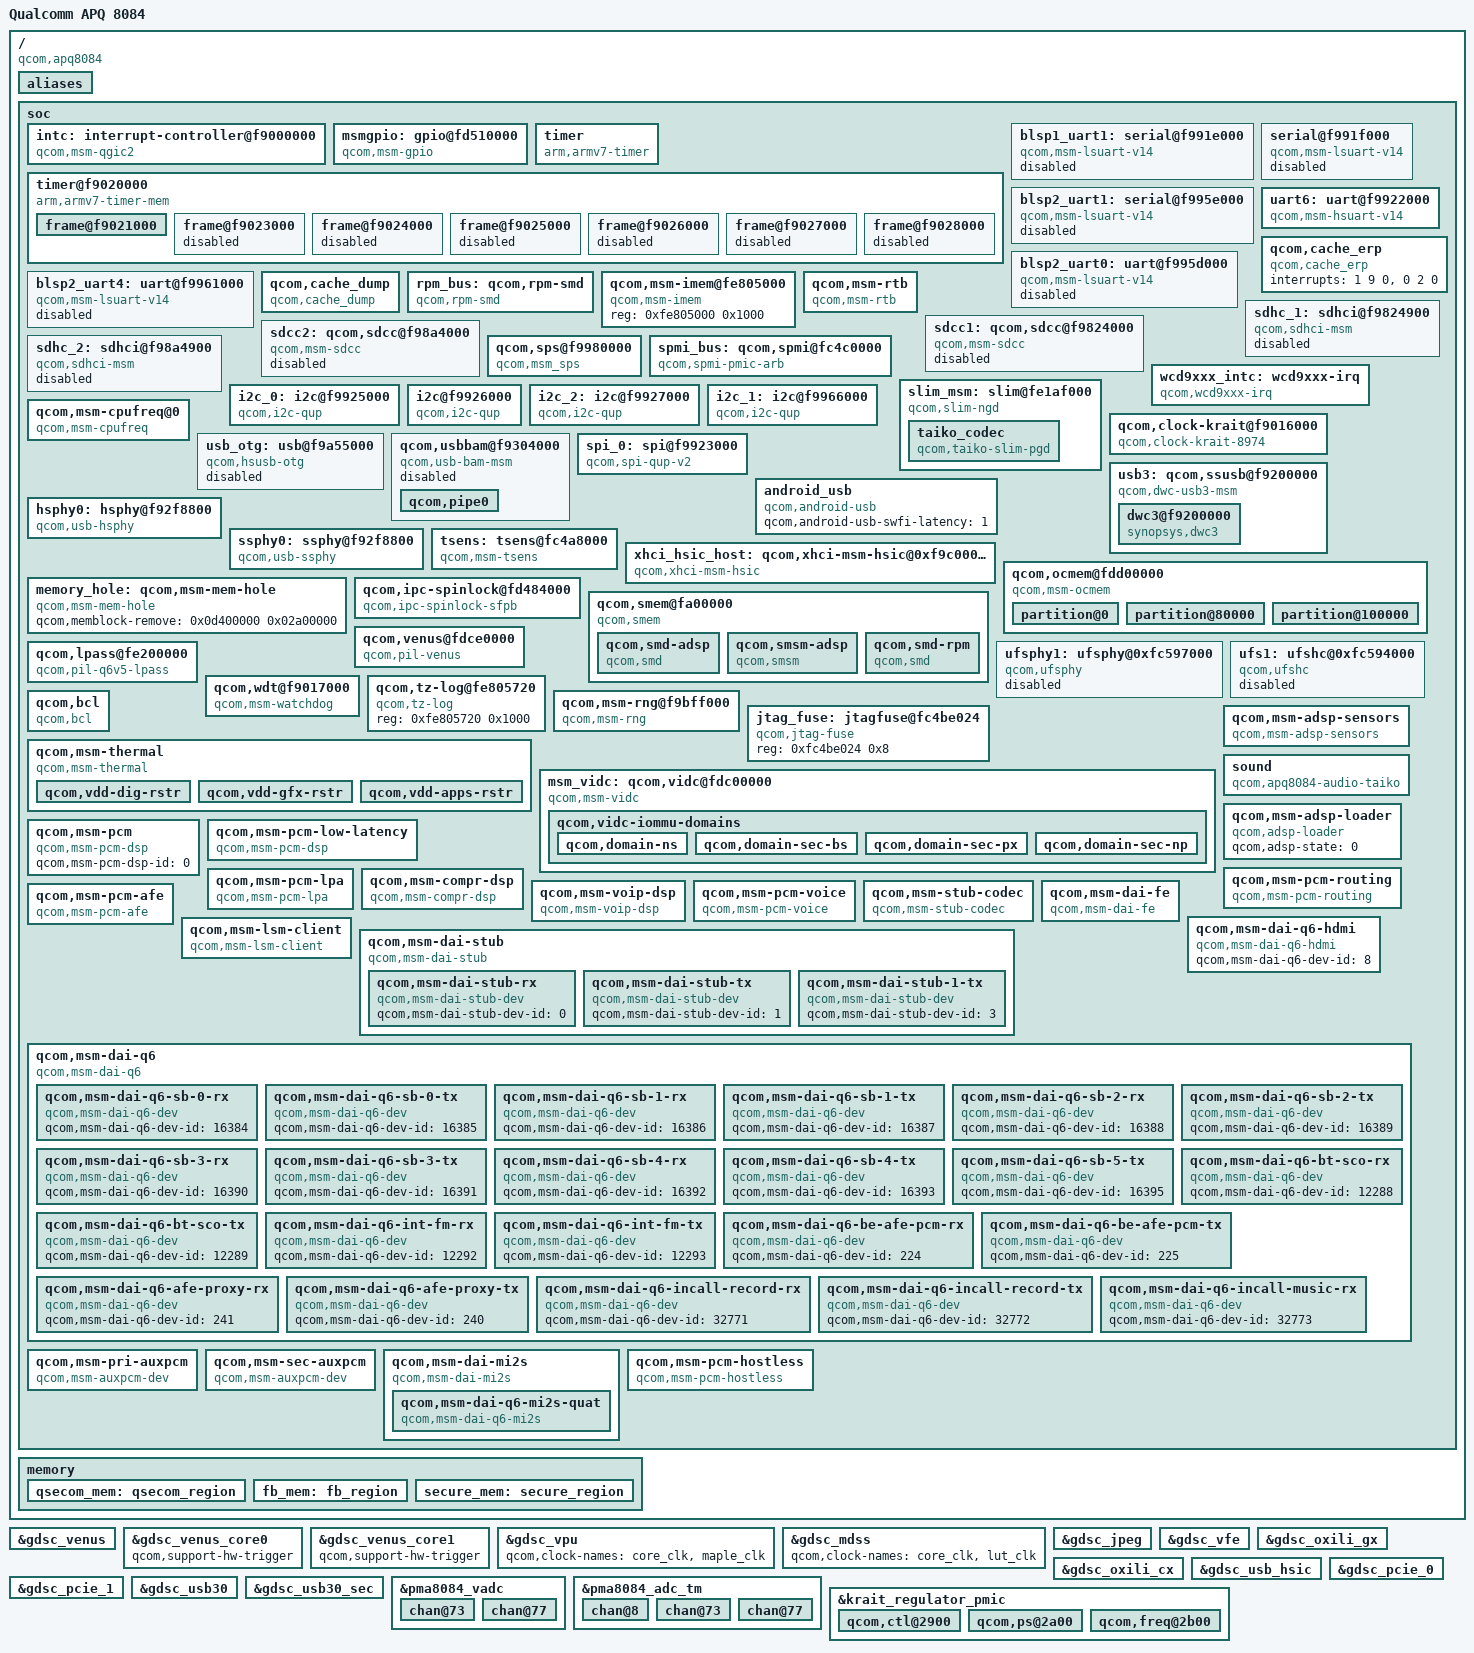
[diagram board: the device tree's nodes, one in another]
/* Copyright (c) 2013, The Linux Foundation. All rights reserved.
 *
 * This program is free software; you can redistribute it and/or modify
 * it under the terms of the GNU General Public License version 2 and
 * only version 2 as published by the Free Software Foundation.
 *
 * This program is distributed in the hope that it will be useful,
 * but WITHOUT ANY WARRANTY; without even the implied warranty of
 * MERCHANTABILITY or FITNESS FOR A PARTICULAR PURPOSE.  See the
 * GNU General Public License for more details.
 */

/include/ "skeleton64.dtsi"

/ {
	model = "Qualcomm APQ 8084";
	compatible = "qcom,apq8084";
	qcom,msm-id = <178 0x10000>;
	interrupt-parent = <&intc>;

	aliases {
		sdhc1 = &sdhc_1; /* SDC1 eMMC slot */
		sdhc2 = &sdhc_2; /* SDC2 SD card slot */
		spi0 = &spi_0;
	};

	soc: soc { };

	memory {
		#address-cells = <2>;
		#size-cells = <2>;

		qsecom_mem: qsecom_region {
			linux,contiguous-region;
			reg = <0 0 0 0x1100000>;
			label = "qseecom_mem";
                };

		fb_mem: fb_region {
			linux,contiguous-region;
			reg = <0 0 0 0x1000000>;
			label = "fb_mem";
			linux,memory-limit = <0xffffffff>;
		};

		secure_mem: secure_region {
			linux,contiguous-region;
			reg = <0 0 0 0xfc00000>;
			label = "secure_mem";
		};
        };
};

/include/ "msm-gdsc.dtsi"
/include/ "apq8084-ion.dtsi"
/include/ "apq8084-iommu.dtsi"
/include/ "apq8084-iommu-domains.dtsi"
/include/ "apq8084-smp2p.dtsi"
/include/ "apq8084-coresight.dtsi"
/include/ "apq8084-mdss.dtsi"
/include/ "apq8084-gpu.dtsi"
/include/ "apq8084-pm.dtsi"
/include/ "apq8084-bus.dtsi"
/include/ "apq8084-iommu-domains.dtsi"

&soc {
	#address-cells = <1>;
	#size-cells = <1>;
	ranges = <0 0 0 0xffffffff>;

	intc: interrupt-controller@f9000000 {
		compatible = "qcom,msm-qgic2";
		interrupt-controller;
		#interrupt-cells = <3>;
		reg = <0xF9000000 0x1000>,
		      <0xF9002000 0x1000>;
	};

	msmgpio: gpio@fd510000 {
		compatible = "qcom,msm-gpio";
		gpio-controller;
		#gpio-cells = <2>;
		interrupt-controller;
		#interrupt-cells = <2>;
		reg = <0xfd510000 0x4000>;
		ngpio = <146>;
		interrupts = <0 208 0>;
		qcom,direct-connect-irqs = <8>;
	};

	timer {
		compatible = "arm,armv7-timer";
		interrupts = <1 2 0xf08>,
			     <1 3 0xf08>,
			     <1 4 0xf08>,
			     <1 1 0xf08>;
		clock-frequency = <19200000>;
	};

	timer@f9020000 {
		#address-cells = <1>;
		#size-cells = <1>;
		ranges;
		compatible = "arm,armv7-timer-mem";
		reg = <0xf9020000 0x1000>;
		clock-frequency = <19200000>;

		frame@f9021000 {
			frame-number = <0>;
			interrupts = <0 8 0x4>,
				     <0 7 0x4>;
			reg = <0xf9021000 0x1000>,
			      <0xf9022000 0x1000>;
		};

		frame@f9023000 {
			frame-number = <1>;
			interrupts = <0 9 0x4>;
			reg = <0xf9023000 0x1000>;
			status = "disabled";
		};

		frame@f9024000 {
			frame-number = <2>;
			interrupts = <0 10 0x4>;
			reg = <0xf9024000 0x1000>;
			status = "disabled";
		};

		frame@f9025000 {
			frame-number = <3>;
			interrupts = <0 11 0x4>;
			reg = <0xf9025000 0x1000>;
			status = "disabled";
		};

		frame@f9026000 {
			frame-number = <4>;
			interrupts = <0 12 0x4>;
			reg = <0xf9026000 0x1000>;
			status = "disabled";
		};

		frame@f9027000 {
			frame-number = <5>;
			interrupts = <0 13 0x4>;
			reg = <0xf9027000 0x1000>;
			status = "disabled";
		};

		frame@f9028000 {
			frame-number = <6>;
			interrupts = <0 14 0x4>;
			reg = <0xf9028000 0x1000>;
			status = "disabled";
		};
	};

        blsp1_uart1: serial@f991e000 {
		compatible = "qcom,msm-lsuart-v14";
		reg = <0xf991e000 0x1000>;
		interrupts = <0 108 0>;
		status = "disabled";
	};

	blsp2_uart1: serial@f995e000 {
		compatible = "qcom,msm-lsuart-v14";
		reg = <0xf995e000 0x1000>;
		interrupts = <0 114 0>;
		status = "disabled";
	};

	blsp2_uart0: uart@f995d000 {
		compatible = "qcom,msm-lsuart-v14";
		reg = <0xf995d000 0x1000>;
		interrupts = <0 113 0>;
		status = "disabled";

		qcom,msm-bus,name = "blsp2_uart0";
		qcom,msm-bus,num-cases = <2>;
		qcom,msm-bus,num-paths = <1>;
		qcom,msm-bus,vectors-KBps =
				<84 512 0 0>,
				<84 512 500 800>;
	};

	serial@f991f000 {
		compatible = "qcom,msm-lsuart-v14";
		reg = <0xf991f000 0x1000>;
		interrupts = <0 109 0>;
		status = "disabled";
	};

	uart6: uart@f9922000 { /* BLSP1 UART6 */
		compatible = "qcom,msm-hsuart-v14";
		reg = <0xf9922000 0x1000>,
			<0xf9904000 0x19000>;
		reg-names = "core_mem", "bam_mem";
		interrupt-names = "core_irq", "bam_irq", "wakeup_irq";
		#address-cells = <0>;
		interrupt-parent = <&uart6>;
		interrupts = <0 1 2>;
		#interrupt-cells = <1>;
		interrupt-map-mask = <0xffffffff>;
		interrupt-map = <0 &intc 0 112 0
						1 &intc 0 238 0
						2 &msmgpio 44 0>;

		qcom,bam-tx-ep-pipe-index = <10>;
		qcom,bam-rx-ep-pipe-index = <11>;
		qcom,msm-bus,name = "uart6";
		qcom,msm-bus,num-cases = <2>;
		qcom,msm-bus,num-paths = <1>;
		qcom,msm-bus,vectors-KBps =
				<86 512 0 0>,
				<86 512 500 800>;
	};

	blsp2_uart4: uart@f9961000 { /* BLSP2 UART4 */
		compatible = "qcom,msm-lsuart-v14";
		reg = <0xf9961000 0x1000>;
		interrupts = <0 117 0>;
		status = "disabled";

		qcom,msm-bus,name = "blsp2_uart4";
		qcom,msm-bus,num-cases = <2>;
		qcom,msm-bus,num-paths = <1>;
		qcom,msm-bus,vectors-KBps =
				<84 512 0 0>,
				<84 512 500 800>;
	};

	qcom,cache_erp {
		compatible = "qcom,cache_erp";
		interrupts = <1 9 0>, <0 2 0>;
		interrupt-names = "l1_irq", "l2_irq";
	};

	qcom,cache_dump {
		compatible = "qcom,cache_dump";
		qcom,l1-dump-size = <0x100000>;
		qcom,l2-dump-size = <0x500000>;
	};

	rpm_bus: qcom,rpm-smd {
		compatible = "qcom,rpm-smd";
		rpm-channel-name = "rpm_requests";
		rpm-channel-type = <15>; /* SMD_APPS_RPM */
	};

        qcom,msm-imem@fe805000 {
                compatible = "qcom,msm-imem";
                reg = <0xfe805000 0x1000>; /* Address and size of IMEM */
	};

	qcom,msm-rtb {
		compatible = "qcom,msm-rtb";
		qcom,memory-reservation-type = "EBI1";
		qcom,memory-reservation-size = <0x100000>; /* 1M EBI1 buffer */
	};

	sdcc1: qcom,sdcc@f9824000 {
		cell-index = <1>; /* SDC1 eMMC slot */
		compatible = "qcom,msm-sdcc";
		reg = <0xf9824000 0x800>;
		reg-names = "core_mem";
		interrupts = <0 123 0>;
		interrupt-names = "core_irq";

		qcom,bus-width = <8>;
		status = "disabled";
	};

	sdhc_1: sdhci@f9824900 {
		compatible = "qcom,sdhci-msm";
		reg = <0xf9824900 0x1a0>, <0xf9824000 0x800>;
		reg-names = "hc_mem", "core_mem";

		interrupts = <0 123 0>, <0 138 0>;
		interrupt-names = "hc_irq", "pwr_irq";

		qcom,bus-width = <8>;
		status = "disabled";
	};

	sdcc2: qcom,sdcc@f98a4000 {
		cell-index = <2>; /* SDC2 SD card slot */
		compatible = "qcom,msm-sdcc";
		reg = <0xf98a4000 0x800>;
		reg-names = "core_mem";
		interrupts = <0 125 0>;
		interrupt-names = "core_irq";

		qcom,bus-width = <4>;
		status = "disabled";
	};

	sdhc_2: sdhci@f98a4900 {
		compatible = "qcom,sdhci-msm";
		reg = <0xf98a4900 0x11c>, <0xf98a4000 0x800>;
		reg-names = "hc_mem", "core_mem";

		interrupts = <0 125 0>, <0 221 0>;
		interrupt-names = "hc_irq", "pwr_irq";

		qcom,bus-width = <4>;
		status = "disabled";
	};

	qcom,sps@f9980000 {
		compatible = "qcom,msm_sps";
		reg = <0xf9984000 0x15000>,
		      <0xf9999000 0xb000>;
		interrupts = <0 94 0>;
		qcom,pipe-attr-ee;
	};

	spmi_bus: qcom,spmi@fc4c0000 {
		cell-index = <0>;
		compatible = "qcom,spmi-pmic-arb";
		reg-names = "core", "intr", "cnfg";
		reg = <0xfc4cf000 0x1000>,
		      <0Xfc4cb000 0x1000>,
		      <0Xfc4ca000 0x1000>;
		/* 190,ee0_krait_hlos_spmi_periph_irq */
		/* 187,channel_0_krait_hlos_trans_done_irq */
		interrupts = <0 190 0>, <0 187 0>;
		qcom,pmic-arb-ee = <0>;
		qcom,pmic-arb-channel = <0>;
		#address-cells = <1>;
		#size-cells = <0>;
		interrupt-controller;
		#interrupt-cells = <3>;
	};

	wcd9xxx_intc: wcd9xxx-irq {
		compatible = "qcom,wcd9xxx-irq";
		interrupt-controller;
		#interrupt-cells = <1>;
		interrupt-parent = <&msmgpio>;
		interrupts = <104 0>;
		interrupt-names = "cdc-int";
	};

	slim_msm: slim@fe1af000 {
		cell-index = <1>;
		compatible = "qcom,slim-ngd";
		reg = <0xfe1af000 0x35000>,
		      <0xfe184000 0x20000>;
		reg-names = "slimbus_physical", "slimbus_bam_physical";
		interrupts = <0 163 0>, <0 164 0>;
		interrupt-names = "slimbus_irq", "slimbus_bam_irq";
		qcom,apps-ch-pipes = <0x60000000>;
		qcom,ea-pc = <0xb0>;

		taiko_codec {
			compatible = "qcom,taiko-slim-pgd";
			elemental-addr = [00 01 A0 00 17 02];

			interrupt-parent = <&wcd9xxx_intc>;
			interrupts = <0 1 2 3 4 5 6 7 8 9 10 11 12 13 14 15 16
				      17 18 19 20 21 22 23 24 25 26 27 28>;

			qcom,cdc-reset-gpio = <&msmgpio 101 0>;

			cdc-vdd-buck-supply = <&pma8084_s5>;
			qcom,cdc-vdd-buck-voltage = <2150000 2150000>;
			qcom,cdc-vdd-buck-current = <650000>;

			cdc-vdd-tx-h-supply = <&pma8084_s4>;
			qcom,cdc-vdd-tx-h-voltage = <1800000 1800000>;
			qcom,cdc-vdd-tx-h-current = <25000>;

			cdc-vdd-rx-h-supply = <&pma8084_s4>;
			qcom,cdc-vdd-rx-h-voltage = <1800000 1800000>;
			qcom,cdc-vdd-rx-h-current = <25000>;

			cdc-vddpx-1-supply = <&pma8084_s4>;
			qcom,cdc-vddpx-1-voltage = <1800000 1800000>;
			qcom,cdc-vddpx-1-current = <10000>;

			cdc-vdd-a-1p2v-supply = <&pma8084_l1>;
			qcom,cdc-vdd-a-1p2v-voltage = <1225000 1225000>;
			qcom,cdc-vdd-a-1p2v-current = <10000>;

			cdc-vddcx-1-supply = <&pma8084_l1>;
			qcom,cdc-vddcx-1-voltage = <1225000 1225000>;
			qcom,cdc-vddcx-1-current = <10000>;

			cdc-vddcx-2-supply = <&pma8084_l1>;
			qcom,cdc-vddcx-2-voltage = <1225000 1225000>;
			qcom,cdc-vddcx-2-current = <10000>;

			qcom,cdc-static-supplies = "cdc-vdd-buck",
						   "cdc-vdd-tx-h",
						   "cdc-vdd-rx-h",
						   "cdc-vddpx-1",
						   "cdc-vdd-a-1p2v",
						   "cdc-vddcx-1",
						   "cdc-vddcx-2";

			qcom,cdc-micbias-ldoh-v = <0x3>;
			qcom,cdc-micbias-cfilt1-mv = <1800>;
			qcom,cdc-micbias-cfilt2-mv = <2700>;
			qcom,cdc-micbias-cfilt3-mv = <1800>;
			qcom,cdc-micbias1-cfilt-sel = <0x0>;
			qcom,cdc-micbias2-cfilt-sel = <0x1>;
			qcom,cdc-micbias3-cfilt-sel = <0x2>;
			qcom,cdc-micbias4-cfilt-sel = <0x2>;
			qcom,cdc-mclk-clk-rate = <9600000>;
			qcom,cdc-slim-ifd = "taiko-slim-ifd";
			qcom,cdc-slim-ifd-elemental-addr = [00 00 A0 00 17 02];
			qcom,cdc-dmic-sample-rate = <4800000>;
		};
	};

	i2c_0: i2c@f9925000 { /* BLSP1 QUP3 */
		cell-index = <0>;
		compatible = "qcom,i2c-qup";
		#address-cells = <1>;
		#size-cells = <0>;
		reg-names = "qup_phys_addr";
		reg = <0xf9925000 0x1000>;
		interrupt-names = "qup_err_intr";
		interrupts = <0 97 0>;
		qcom,i2c-bus-freq = <100000>;
		qcom,i2c-src-freq = <50000000>;
		qcom,sda-gpio = <&msmgpio 10 0>;
		qcom,scl-gpio = <&msmgpio 11 0>;
		qcom,master-id = <86>;
	};

	i2c@f9926000 { /* BLSP-1 QUP-4 */
		cell-index = <3>;
		compatible = "qcom,i2c-qup";
		reg = <0xf9926000 0x1000>;
		#address-cells = <1>;
		#size-cells = <0>;
		reg-names = "qup_phys_addr";
		interrupts = <0 98 0>;
		interrupt-names = "qup_err_intr";
		qcom,i2c-bus-freq = <400000>;
		qcom,i2c-src-freq = <19200000>;
		qcom,sda-gpio = <&msmgpio 29 0>;
		qcom,scl-gpio = <&msmgpio 30 0>;
		qcom,master-id = <86>;
	};

	i2c_2: i2c@f9927000 { /* BLSP1 QUP5 */
		cell-index = <2>;
		compatible = "qcom,i2c-qup";
		#address-cells = <1>;
		#size-cells = <0>;
		reg-names = "qup_phys_addr";
		reg = <0xf9927000 0x1000>;
		interrupt-names = "qup_err_intr";
		interrupts = <0 99 0>;
		qcom,i2c-bus-freq = <100000>;
		qcom,i2c-src-freq = <19200000>;
		qcom,sda-gpio = <&msmgpio 41 0>;
		qcom,scl-gpio = <&msmgpio 42 0>;
		qcom,master-id = <86>;
	};

	i2c_1: i2c@f9966000 { /* BLSP2 QUP4 */
		cell-index = <1>;
		compatible = "qcom,i2c-qup";
		#address-cells = <1>;
		#size-cells = <0>;
		reg-names = "qup_phys_addr";
		reg = <0xf9966000 0x1000>;
		interrupt-names = "qup_err_intr";
		interrupts = <0 104 0>;
		qcom,i2c-bus-freq = <100000>;
		qcom,i2c-src-freq = <50000000>;
		qcom,sda-gpio = <&msmgpio 61 0>;
		qcom,scl-gpio = <&msmgpio 62 0>;
		qcom,master-id = <84>;
	};

	qcom,clock-krait@f9016000 {
		compatible = "qcom,clock-krait-8974";
		reg = <0xf9016000 0x20>,
			<0xf908a000 0x20>,
			<0xf909a000 0x20>,
			<0xf90aa000 0x20>,
			<0xf90ba000 0x20>,
			<0xfc4b80b0 0x08>;
		reg-names = "hfpll_l2_clk", "hfpll0_clk",
				"hfpll1_clk", "hfpll2_clk",
				"hfpll3_clk", "efuse";
		cpu0-supply = <&krait0_vreg>;
		cpu1-supply = <&krait1_vreg>;
		cpu2-supply = <&krait2_vreg>;
		cpu3-supply = <&krait3_vreg>;
		l2-dig-supply = <&pma8084_s2_corner_ao>;
		hfpll-dig-supply = <&pma8084_s2_corner_ao>;
		hfpll-analog-supply = <&pma8084_l12_ao>;
		qcom,hfpll-config-val = <0x04D0405D>;
		qcom,hfpll-user-vco-mask = <0x00100000>;

		qcom,l2-fmax =
			<          0 0			 >,
			<          0 4 /* SVS_SOC */	 >,
			< 1036800000 5 /* NORMAL */	 >,
			< 1728000000 7 /* SUPER_TURBO */ >;

		/*   2.5GHz   */
		qcom,speed1-pvs0-bin-v0 =
			< 0 0 0 >,
			< 300000000 800000 76 >,
			< 345600000 800000 87 >,
			< 422400000 800000 106 >,
			< 499200000 800000 125 >,
			< 576000000 800000 145 >,
			< 652800000 800000 164 >,
			< 729600000 800000 183 >,
			< 806400000 800000 202 >,
			< 883200000 800000 222 >,
			< 960000000 800000 241 >,
			< 1036800000 815000 263 >,
			< 1113600000 830000 286 >,
			< 1190400000 845000 310 >,
			< 1267200000 860000 334 >,
			< 1344000000 875000 359 >,
			< 1420800000 890000 384 >,
			< 1497600000 905000 409 >,
			< 1574400000 920000 436 >,
			< 1651200000 935000 462 >,
			< 1728000000 950000 489 >,
			< 1804800000 965000 517 >;

		qcom,speed1-pvs1-bin-v0 =
			< 0 0 0 >,
			< 300000000 800000 76 >,
			< 345600000 800000 87 >,
			< 422400000 800000 106 >,
			< 499200000 800000 125 >,
			< 576000000 800000 145 >,
			< 652800000 800000 164 >,
			< 729600000 800000 183 >,
			< 806400000 800000 202 >,
			< 883200000 800000 222 >,
			< 960000000 800000 241 >,
			< 1036800000 810000 263 >,
			< 1113600000 825000 286 >,
			< 1190400000 840000 310 >,
			< 1267200000 855000 334 >,
			< 1344000000 870000 359 >,
			< 1420800000 885000 384 >,
			< 1497600000 900000 409 >,
			< 1574400000 910000 436 >,
			< 1651200000 925000 462 >,
			< 1728000000 940000 489 >,
			< 1804800000 955000 517 >;

		qcom,speed1-pvs2-bin-v0 =
			< 0 0 0 >,
			< 300000000 800000 76 >,
			< 345600000 800000 87 >,
			< 422400000 800000 106 >,
			< 499200000 800000 125 >,
			< 576000000 800000 145 >,
			< 652800000 800000 164 >,
			< 729600000 800000 183 >,
			< 806400000 800000 202 >,
			< 883200000 800000 222 >,
			< 960000000 800000 241 >,
			< 1036800000 805000 263 >,
			< 1113600000 820000 286 >,
			< 1190400000 835000 310 >,
			< 1267200000 845000 334 >,
			< 1344000000 860000 359 >,
			< 1420800000 875000 384 >,
			< 1497600000 890000 409 >,
			< 1574400000 905000 436 >,
			< 1651200000 920000 462 >,
			< 1728000000 935000 489 >,
			< 1804800000 950000 517 >;

		qcom,speed1-pvs3-bin-v0 =
			< 0 0 0 >,
			< 300000000 800000 76 >,
			< 345600000 800000 87 >,
			< 422400000 800000 106 >,
			< 499200000 800000 125 >,
			< 576000000 800000 145 >,
			< 652800000 800000 164 >,
			< 729600000 800000 183 >,
			< 806400000 800000 202 >,
			< 883200000 800000 222 >,
			< 960000000 800000 241 >,
			< 1036800000 800000 263 >,
			< 1113600000 815000 286 >,
			< 1190400000 825000 310 >,
			< 1267200000 840000 334 >,
			< 1344000000 855000 359 >,
			< 1420800000 870000 384 >,
			< 1497600000 885000 409 >,
			< 1574400000 895000 436 >,
			< 1651200000 910000 462 >,
			< 1728000000 925000 489 >,
			< 1804800000 940000 517 >;

		qcom,speed1-pvs4-bin-v0 =
			< 0 0 0 >,
			< 300000000 800000 76 >,
			< 345600000 800000 87 >,
			< 422400000 800000 106 >,
			< 499200000 800000 125 >,
			< 576000000 800000 145 >,
			< 652800000 800000 164 >,
			< 729600000 800000 183 >,
			< 806400000 800000 202 >,
			< 883200000 800000 222 >,
			< 960000000 800000 241 >,
			< 1036800000 800000 263 >,
			< 1113600000 805000 286 >,
			< 1190400000 820000 310 >,
			< 1267200000 835000 334 >,
			< 1344000000 850000 359 >,
			< 1420800000 860000 384 >,
			< 1497600000 875000 409 >,
			< 1574400000 890000 436 >,
			< 1651200000 905000 462 >,
			< 1728000000 915000 489 >,
			< 1804800000 930000 517 >;

		qcom,speed1-pvs5-bin-v0 =
			< 0 0 0 >,
			< 300000000 775000 76 >,
			< 345600000 775000 87 >,
			< 422400000 775000 106 >,
			< 499200000 775000 125 >,
			< 576000000 775000 145 >,
			< 652800000 775000 164 >,
			< 729600000 775000 183 >,
			< 806400000 775000 202 >,
			< 883200000 775000 222 >,
			< 960000000 775000 241 >,
			< 1036800000 790000 263 >,
			< 1113600000 800000 286 >,
			< 1190400000 815000 310 >,
			< 1267200000 830000 334 >,
			< 1344000000 840000 359 >,
			< 1420800000 855000 384 >,
			< 1497600000 870000 409 >,
			< 1574400000 880000 436 >,
			< 1651200000 895000 462 >,
			< 1728000000 910000 489 >,
			< 1804800000 920000 517 >;

		qcom,speed1-pvs6-bin-v0 =
			< 0 0 0 >,
			< 300000000 775000 76 >,
			< 345600000 775000 87 >,
			< 422400000 775000 106 >,
			< 499200000 775000 125 >,
			< 576000000 775000 145 >,
			< 652800000 775000 164 >,
			< 729600000 775000 183 >,
			< 806400000 775000 202 >,
			< 883200000 775000 222 >,
			< 960000000 775000 241 >,
			< 1036800000 785000 263 >,
			< 1113600000 795000 286 >,
			< 1190400000 810000 310 >,
			< 1267200000 820000 334 >,
			< 1344000000 835000 359 >,
			< 1420800000 850000 384 >,
			< 1497600000 860000 409 >,
			< 1574400000 875000 436 >,
			< 1651200000 885000 462 >,
			< 1728000000 900000 489 >,
			< 1804800000 915000 517 >;

		qcom,speed1-pvs7-bin-v0 =
			< 0 0 0 >,
			< 300000000 775000 76 >,
			< 345600000 775000 87 >,
			< 422400000 775000 106 >,
			< 499200000 775000 125 >,
			< 576000000 775000 145 >,
			< 652800000 775000 164 >,
			< 729600000 775000 183 >,
			< 806400000 775000 202 >,
			< 883200000 775000 222 >,
			< 960000000 775000 241 >,
			< 1036800000 780000 263 >,
			< 1113600000 790000 286 >,
			< 1190400000 805000 310 >,
			< 1267200000 815000 334 >,
			< 1344000000 830000 359 >,
			< 1420800000 840000 384 >,
			< 1497600000 855000 409 >,
			< 1574400000 865000 436 >,
			< 1651200000 880000 462 >,
			< 1728000000 890000 489 >,
			< 1804800000 905000 517 >;

		qcom,speed1-pvs8-bin-v0 =
			< 0 0 0 >,
			< 300000000 775000 76 >,
			< 345600000 775000 87 >,
			< 422400000 775000 106 >,
			< 499200000 775000 125 >,
			< 576000000 775000 145 >,
			< 652800000 775000 164 >,
			< 729600000 775000 183 >,
			< 806400000 775000 202 >,
			< 883200000 775000 222 >,
			< 960000000 775000 241 >,
			< 1036800000 775000 263 >,
			< 1113600000 785000 286 >,
			< 1190400000 795000 310 >,
			< 1267200000 810000 334 >,
			< 1344000000 820000 359 >,
			< 1420800000 835000 384 >,
			< 1497600000 845000 409 >,
			< 1574400000 860000 436 >,
			< 1651200000 870000 462 >,
			< 1728000000 885000 489 >,
			< 1804800000 895000 517 >;

		qcom,speed1-pvs9-bin-v0 =
			< 0 0 0 >,
			< 300000000 750000 76 >,
			< 345600000 750000 87 >,
			< 422400000 750000 106 >,
			< 499200000 750000 125 >,
			< 576000000 750000 145 >,
			< 652800000 750000 164 >,
			< 729600000 750000 183 >,
			< 806400000 750000 202 >,
			< 883200000 750000 222 >,
			< 960000000 755000 241 >,
			< 1036800000 765000 263 >,
			< 1113600000 780000 286 >,
			< 1190400000 790000 310 >,
			< 1267200000 805000 334 >,
			< 1344000000 815000 359 >,
			< 1420800000 825000 384 >,
			< 1497600000 840000 409 >,
			< 1574400000 850000 436 >,
			< 1651200000 865000 462 >,
			< 1728000000 875000 489 >,
			< 1804800000 885000 517 >;

		qcom,speed1-pvs10-bin-v0 =
			< 0 0 0 >,
			< 300000000 750000 76 >,
			< 345600000 750000 87 >,
			< 422400000 750000 106 >,
			< 499200000 750000 125 >,
			< 576000000 750000 145 >,
			< 652800000 750000 164 >,
			< 729600000 750000 183 >,
			< 806400000 750000 202 >,
			< 883200000 750000 222 >,
			< 960000000 750000 241 >,
			< 1036800000 760000 263 >,
			< 1113600000 775000 286 >,
			< 1190400000 785000 310 >,
			< 1267200000 795000 334 >,
			< 1344000000 810000 359 >,
			< 1420800000 820000 384 >,
			< 1497600000 830000 409 >,
			< 1574400000 845000 436 >,
			< 1651200000 855000 462 >,
			< 1728000000 865000 489 >,
			< 1804800000 880000 517 >;

		qcom,speed1-pvs11-bin-v0 =
			< 0 0 0 >,
			< 300000000 750000 76 >,
			< 345600000 750000 87 >,
			< 422400000 750000 106 >,
			< 499200000 750000 125 >,
			< 576000000 750000 145 >,
			< 652800000 750000 164 >,
			< 729600000 750000 183 >,
			< 806400000 750000 202 >,
			< 883200000 750000 222 >,
			< 960000000 750000 241 >,
			< 1036800000 755000 263 >,
			< 1113600000 770000 286 >,
			< 1190400000 780000 310 >,
			< 1267200000 790000 334 >,
			< 1344000000 800000 359 >,
			< 1420800000 815000 384 >,
			< 1497600000 825000 409 >,
			< 1574400000 835000 436 >,
			< 1651200000 845000 462 >,
			< 1728000000 860000 489 >,
			< 1804800000 870000 517 >;

		qcom,speed1-pvs12-bin-v0 =
			< 0 0 0 >,
			< 300000000 750000 76 >,
			< 345600000 750000 87 >,
			< 422400000 750000 106 >,
			< 499200000 750000 125 >,
			< 576000000 750000 145 >,
			< 652800000 750000 164 >,
			< 729600000 750000 183 >,
			< 806400000 750000 202 >,
			< 883200000 750000 222 >,
			< 960000000 750000 241 >,
			< 1036800000 750000 263 >,
			< 1113600000 760000 286 >,
			< 1190400000 775000 310 >,
			< 1267200000 785000 334 >,
			< 1344000000 795000 359 >,
			< 1420800000 805000 384 >,
			< 1497600000 815000 409 >,
			< 1574400000 830000 436 >,
			< 1651200000 840000 462 >,
			< 1728000000 850000 489 >,
			< 1804800000 860000 517 >;

		qcom,speed1-pvs13-bin-v0 =
			< 0 0 0 >,
			< 300000000 725000 76 >,
			< 345600000 725000 87 >,
			< 422400000 725000 106 >,
			< 499200000 725000 125 >,
			< 576000000 725000 145 >,
			< 652800000 725000 164 >,
			< 729600000 725000 183 >,
			< 806400000 725000 202 >,
			< 883200000 725000 222 >,
			< 960000000 735000 241 >,
			< 1036800000 745000 263 >,
			< 1113600000 755000 286 >,
			< 1190400000 765000 310 >,
			< 1267200000 780000 334 >,
			< 1344000000 790000 359 >,
			< 1420800000 800000 384 >,
			< 1497600000 810000 409 >,
			< 1574400000 820000 436 >,
			< 1651200000 830000 462 >,
			< 1728000000 840000 489 >,
			< 1804800000 850000 517 >;

		qcom,speed1-pvs14-bin-v0 =
			< 0 0 0 >,
			< 300000000 725000 76 >,
			< 345600000 725000 87 >,
			< 422400000 725000 106 >,
			< 499200000 725000 125 >,
			< 576000000 725000 145 >,
			< 652800000 725000 164 >,
			< 729600000 725000 183 >,
			< 806400000 725000 202 >,
			< 883200000 725000 222 >,
			< 960000000 730000 241 >,
			< 1036800000 740000 263 >,
			< 1113600000 750000 286 >,
			< 1190400000 760000 310 >,
			< 1267200000 770000 334 >,
			< 1344000000 780000 359 >,
			< 1420800000 790000 384 >,
			< 1497600000 800000 409 >,
			< 1574400000 815000 436 >,
			< 1651200000 825000 462 >,
			< 1728000000 835000 489 >,
			< 1804800000 845000 517 >;

		qcom,speed1-pvs15-bin-v0 =
			< 0 0 0 >,
			< 300000000 725000 76 >,
			< 345600000 725000 87 >,
			< 422400000 725000 106 >,
			< 499200000 725000 125 >,
			< 576000000 725000 145 >,
			< 652800000 725000 164 >,
			< 729600000 725000 183 >,
			< 806400000 725000 202 >,
			< 883200000 725000 222 >,
			< 960000000 725000 241 >,
			< 1036800000 735000 263 >,
			< 1113600000 745000 286 >,
			< 1190400000 755000 310 >,
			< 1267200000 765000 334 >,
			< 1344000000 775000 359 >,
			< 1420800000 785000 384 >,
			< 1497600000 795000 409 >,
			< 1574400000 805000 436 >,
			< 1651200000 815000 462 >,
			< 1728000000 825000 489 >,
			< 1804800000 835000 517 >;

		/*   2.3GHz   */
		qcom,speed0-pvs0-bin-v0 =
			< 0 0 0 >,
			< 300000000 800000 76 >,
			< 345600000 800000 87 >,
			< 422400000 800000 106 >,
			< 499200000 800000 125 >,
			< 576000000 800000 145 >,
			< 652800000 800000 164 >,
			< 729600000 800000 183 >,
			< 806400000 815000 205 >,
			< 883200000 830000 227 >,
			< 960000000 845000 250 >,
			< 1036800000 860000 273 >,
			< 1113600000 875000 298 >,
			< 1190400000 890000 322 >,
			< 1267200000 905000 346 >,
			< 1344000000 920000 372 >,
			< 1420800000 935000 398 >,
			< 1497600000 950000 424 >,
			< 1574400000 965000 451 >,
			< 1651200000 980000 479 >,
			< 1728000000 995000 506 >,
			< 1804800000 1010000 535 >;

		qcom,speed0-pvs1-bin-v0 =
			< 0 0 0 >,
			< 300000000 800000 76 >,
			< 345600000 800000 87 >,
			< 422400000 800000 106 >,
			< 499200000 800000 125 >,
			< 576000000 800000 145 >,
			< 652800000 800000 164 >,
			< 729600000 800000 183 >,
			< 806400000 810000 205 >,
			< 883200000 825000 227 >,
			< 960000000 840000 250 >,
			< 1036800000 855000 273 >,
			< 1113600000 870000 298 >,
			< 1190400000 885000 322 >,
			< 1267200000 900000 346 >,
			< 1344000000 910000 372 >,
			< 1420800000 925000 398 >,
			< 1497600000 940000 424 >,
			< 1574400000 955000 451 >,
			< 1651200000 970000 479 >,
			< 1728000000 985000 506 >,
			< 1804800000 1000000 535 >;

		qcom,speed0-pvs2-bin-v0 =
			< 0 0 0 >,
			< 300000000 800000 76 >,
			< 345600000 800000 87 >,
			< 422400000 800000 106 >,
			< 499200000 800000 125 >,
			< 576000000 800000 145 >,
			< 652800000 800000 164 >,
			< 729600000 800000 183 >,
			< 806400000 805000 205 >,
			< 883200000 820000 227 >,
			< 960000000 835000 250 >,
			< 1036800000 845000 273 >,
			< 1113600000 860000 298 >,
			< 1190400000 875000 322 >,
			< 1267200000 890000 346 >,
			< 1344000000 905000 372 >,
			< 1420800000 920000 398 >,
			< 1497600000 935000 424 >,
			< 1574400000 950000 451 >,
			< 1651200000 960000 479 >,
			< 1728000000 975000 506 >,
			< 1804800000 990000 535 >;

		qcom,speed0-pvs3-bin-v0 =
			< 0 0 0 >,
			< 300000000 800000 76 >,
			< 345600000 800000 87 >,
			< 422400000 800000 106 >,
			< 499200000 800000 125 >,
			< 576000000 800000 145 >,
			< 652800000 800000 164 >,
			< 729600000 800000 183 >,
			< 806400000 800000 205 >,
			< 883200000 815000 227 >,
			< 960000000 825000 250 >,
			< 1036800000 840000 273 >,
			< 1113600000 855000 298 >,
			< 1190400000 870000 322 >,
			< 1267200000 885000 346 >,
			< 1344000000 895000 372 >,
			< 1420800000 910000 398 >,
			< 1497600000 925000 424 >,
			< 1574400000 940000 451 >,
			< 1651200000 955000 479 >,
			< 1728000000 965000 506 >,
			< 1804800000 980000 535 >;

		qcom,speed0-pvs4-bin-v0 =
			< 0 0 0 >,
			< 300000000 800000 76 >,
			< 345600000 800000 87 >,
			< 422400000 800000 106 >,
			< 499200000 800000 125 >,
			< 576000000 800000 145 >,
			< 652800000 800000 164 >,
			< 729600000 800000 183 >,
			< 806400000 800000 205 >,
			< 883200000 805000 227 >,
			< 960000000 820000 250 >,
			< 1036800000 835000 273 >,
			< 1113600000 850000 298 >,
			< 1190400000 860000 322 >,
			< 1267200000 875000 346 >,
			< 1344000000 890000 372 >,
			< 1420800000 905000 398 >,
			< 1497600000 915000 424 >,
			< 1574400000 930000 451 >,
			< 1651200000 945000 479 >,
			< 1728000000 960000 506 >,
			< 1804800000 970000 535 >;

		qcom,speed0-pvs5-bin-v0 =
			< 0 0 0 >,
			< 300000000 775000 76 >,
			< 345600000 775000 87 >,
			< 422400000 775000 106 >,
			< 499200000 775000 125 >,
			< 576000000 775000 145 >,
			< 652800000 775000 164 >,
			< 729600000 775000 183 >,
			< 806400000 790000 205 >,
			< 883200000 800000 227 >,
			< 960000000 815000 250 >,
			< 1036800000 830000 273 >,
			< 1113600000 840000 298 >,
			< 1190400000 855000 322 >,
			< 1267200000 870000 346 >,
			< 1344000000 880000 372 >,
			< 1420800000 895000 398 >,
			< 1497600000 910000 424 >,
			< 1574400000 920000 451 >,
			< 1651200000 935000 479 >,
			< 1728000000 950000 506 >,
			< 1804800000 960000 535 >;

		qcom,speed0-pvs6-bin-v0 =
			< 0 0 0 >,
			< 300000000 775000 76 >,
			< 345600000 775000 87 >,
			< 422400000 775000 106 >,
			< 499200000 775000 125 >,
			< 576000000 775000 145 >,
			< 652800000 775000 164 >,
			< 729600000 775000 183 >,
			< 806400000 785000 205 >,
			< 883200000 795000 227 >,
			< 960000000 810000 250 >,
			< 1036800000 820000 273 >,
			< 1113600000 835000 298 >,
			< 1190400000 850000 322 >,
			< 1267200000 860000 346 >,
			< 1344000000 875000 372 >,
			< 1420800000 885000 398 >,
			< 1497600000 900000 424 >,
			< 1574400000 915000 451 >,
			< 1651200000 925000 479 >,
			< 1728000000 940000 506 >,
			< 1804800000 950000 535 >;

		qcom,speed0-pvs7-bin-v0 =
			< 0 0 0 >,
			< 300000000 775000 76 >,
			< 345600000 775000 87 >,
			< 422400000 775000 106 >,
			< 499200000 775000 125 >,
			< 576000000 775000 145 >,
			< 652800000 775000 164 >,
			< 729600000 775000 183 >,
			< 806400000 780000 205 >,
			< 883200000 790000 227 >,
			< 960000000 805000 250 >,
			< 1036800000 815000 273 >,
			< 1113600000 830000 298 >,
			< 1190400000 840000 322 >,
			< 1267200000 855000 346 >,
			< 1344000000 865000 372 >,
			< 1420800000 880000 398 >,
			< 1497600000 890000 424 >,
			< 1574400000 905000 451 >,
			< 1651200000 915000 479 >,
			< 1728000000 930000 506 >,
			< 1804800000 940000 535 >;

		qcom,speed0-pvs8-bin-v0 =
			< 0 0 0 >,
			< 300000000 775000 76 >,
			< 345600000 775000 87 >,
			< 422400000 775000 106 >,
			< 499200000 775000 125 >,
			< 576000000 775000 145 >,
			< 652800000 775000 164 >,
			< 729600000 775000 183 >,
			< 806400000 775000 205 >,
			< 883200000 785000 227 >,
			< 960000000 795000 250 >,
			< 1036800000 810000 273 >,
			< 1113600000 820000 298 >,
			< 1190400000 835000 322 >,
			< 1267200000 845000 346 >,
			< 1344000000 860000 372 >,
			< 1420800000 870000 398 >,
			< 1497600000 885000 424 >,
			< 1574400000 895000 451 >,
			< 1651200000 910000 479 >,
			< 1728000000 920000 506 >,
			< 1804800000 935000 535 >;

		qcom,speed0-pvs9-bin-v0 =
			< 0 0 0 >,
			< 300000000 750000 76 >,
			< 345600000 750000 87 >,
			< 422400000 750000 106 >,
			< 499200000 750000 125 >,
			< 576000000 750000 145 >,
			< 652800000 750000 164 >,
			< 729600000 755000 183 >,
			< 806400000 765000 205 >,
			< 883200000 780000 227 >,
			< 960000000 790000 250 >,
			< 1036800000 805000 273 >,
			< 1113600000 815000 298 >,
			< 1190400000 825000 322 >,
			< 1267200000 840000 346 >,
			< 1344000000 850000 372 >,
			< 1420800000 865000 398 >,
			< 1497600000 875000 424 >,
			< 1574400000 885000 451 >,
			< 1651200000 900000 479 >,
			< 1728000000 910000 506 >,
			< 1804800000 925000 535 >;

		qcom,speed0-pvs10-bin-v0 =
			< 0 0 0 >,
			< 300000000 750000 76 >,
			< 345600000 750000 87 >,
			< 422400000 750000 106 >,
			< 499200000 750000 125 >,
			< 576000000 750000 145 >,
			< 652800000 750000 164 >,
			< 729600000 750000 183 >,
			< 806400000 760000 205 >,
			< 883200000 775000 227 >,
			< 960000000 785000 250 >,
			< 1036800000 795000 273 >,
			< 1113600000 810000 298 >,
			< 1190400000 820000 322 >,
			< 1267200000 830000 346 >,
			< 1344000000 845000 372 >,
			< 1420800000 855000 398 >,
			< 1497600000 865000 424 >,
			< 1574400000 880000 451 >,
			< 1651200000 890000 479 >,
			< 1728000000 900000 506 >,
			< 1804800000 915000 535 >;

		qcom,speed0-pvs11-bin-v0 =
			< 0 0 0 >,
			< 300000000 750000 76 >,
			< 345600000 750000 87 >,
			< 422400000 750000 106 >,
			< 499200000 750000 125 >,
			< 576000000 750000 145 >,
			< 652800000 750000 164 >,
			< 729600000 750000 183 >,
			< 806400000 755000 205 >,
			< 883200000 770000 227 >,
			< 960000000 780000 250 >,
			< 1036800000 790000 273 >,
			< 1113600000 800000 298 >,
			< 1190400000 815000 322 >,
			< 1267200000 825000 346 >,
			< 1344000000 835000 372 >,
			< 1420800000 845000 398 >,
			< 1497600000 860000 424 >,
			< 1574400000 870000 451 >,
			< 1651200000 880000 479 >,
			< 1728000000 890000 506 >,
			< 1804800000 905000 535 >;

		qcom,speed0-pvs12-bin-v0 =
			< 0 0 0 >,
			< 300000000 750000 76 >,
			< 345600000 750000 87 >,
			< 422400000 750000 106 >,
			< 499200000 750000 125 >,
			< 576000000 750000 145 >,
			< 652800000 750000 164 >,
			< 729600000 750000 183 >,
			< 806400000 750000 205 >,
			< 883200000 760000 227 >,
			< 960000000 775000 250 >,
			< 1036800000 785000 273 >,
			< 1113600000 795000 298 >,
			< 1190400000 805000 322 >,
			< 1267200000 815000 346 >,
			< 1344000000 830000 372 >,
			< 1420800000 840000 398 >,
			< 1497600000 850000 424 >,
			< 1574400000 860000 451 >,
			< 1651200000 870000 479 >,
			< 1728000000 885000 506 >,
			< 1804800000 895000 535 >;

		qcom,speed0-pvs13-bin-v0 =
			< 0 0 0 >,
			< 300000000 725000 76 >,
			< 345600000 725000 87 >,
			< 422400000 725000 106 >,
			< 499200000 725000 125 >,
			< 576000000 725000 145 >,
			< 652800000 725000 164 >,
			< 729600000 735000 183 >,
			< 806400000 745000 205 >,
			< 883200000 755000 227 >,
			< 960000000 765000 250 >,
			< 1036800000 780000 273 >,
			< 1113600000 790000 298 >,
			< 1190400000 800000 322 >,
			< 1267200000 810000 346 >,
			< 1344000000 820000 372 >,
			< 1420800000 830000 398 >,
			< 1497600000 840000 424 >,
			< 1574400000 850000 451 >,
			< 1651200000 865000 479 >,
			< 1728000000 875000 506 >,
			< 1804800000 885000 535 >;

		qcom,speed0-pvs14-bin-v0 =
			< 0 0 0 >,
			< 300000000 725000 76 >,
			< 345600000 725000 87 >,
			< 422400000 725000 106 >,
			< 499200000 725000 125 >,
			< 576000000 725000 145 >,
			< 652800000 725000 164 >,
			< 729600000 730000 183 >,
			< 806400000 740000 205 >,
			< 883200000 750000 227 >,
			< 960000000 760000 250 >,
			< 1036800000 770000 273 >,
			< 1113600000 780000 298 >,
			< 1190400000 790000 322 >,
			< 1267200000 800000 346 >,
			< 1344000000 815000 372 >,
			< 1420800000 825000 398 >,
			< 1497600000 835000 424 >,
			< 1574400000 845000 451 >,
			< 1651200000 855000 479 >,
			< 1728000000 865000 506 >,
			< 1804800000 875000 535 >;

		qcom,speed0-pvs15-bin-v0 =
			< 0 0 0 >,
			< 300000000 725000 76 >,
			< 345600000 725000 87 >,
			< 422400000 725000 106 >,
			< 499200000 725000 125 >,
			< 576000000 725000 145 >,
			< 652800000 725000 164 >,
			< 729600000 725000 183 >,
			< 806400000 735000 205 >,
			< 883200000 745000 227 >,
			< 960000000 755000 250 >,
			< 1036800000 765000 273 >,
			< 1113600000 775000 298 >,
			< 1190400000 785000 322 >,
			< 1267200000 795000 346 >,
			< 1344000000 805000 372 >,
			< 1420800000 815000 398 >,
			< 1497600000 825000 424 >,
			< 1574400000 835000 451 >,
			< 1651200000 845000 479 >,
			< 1728000000 855000 506 >,
			< 1804800000 865000 535 >;
	};

	qcom,msm-cpufreq@0 {
		reg = <0 4>;
		compatible = "qcom,msm-cpufreq";
		qcom,cpu-mem-ports = <1 512>;
		qcom,cpufreq-table =
			<  300000  300000  600 /*  75 MHz */ >,
			<  422400  422400 1200 /* 150 MHz */ >,
			<  652800  499200 1600 /* 200 MHz */ >,
			<  729600  576000 2456 /* 307 MHz */ >,
			<  883200  576000 2456 /* 307 MHz */ >,
			<  960000  960000 3680 /* 460 MHz */ >,
			< 1036800 1036800 3680 /* 460 MHz */ >,
			< 1190400 1036800 3680 /* 460 MHz */ >,
			< 1267200 1267200 6400 /* 800 MHz */ >,
			< 1497600 1497600 6400 /* 800 MHz */ >,
			< 1574400 1574400 6400 /* 800 MHz */ >,
			< 1728000 1651200 6400 /* 800 MHz */ >,
			< 1958400 1728000 7448 /* 931 MHz */ >,
			< 2265600 1728000 7448 /* 931 MHz */ >;
	};

	usb_otg: usb@f9a55000 {
		status = "disabled";
		compatible = "qcom,hsusb-otg";

		reg = <0xf9a55000 0x400>;
		interrupts = <0 134 0 0 140 0>;
		interrupt-names = "core_irq", "async_irq";
		HSUSB_VDDCX-supply = <&pma8084_s1>;
		HSUSB_1p8-supply = <&pma8084_l6>;
		HSUSB_3p3-supply = <&pma8084_l24>;
		qcom,vdd-voltage-level = <0 900000 1050000>;

		qcom,hsusb-otg-phy-type = <2>;
		qcom,hsusb-otg-mode = <1>;
		qcom,hsusb-otg-otg-control = <3>;
		qcom,hsusb-otg-default-mode = <1>;
		qcom,dp-manual-pullup;

		qcom,msm-bus,name = "usb2";
		qcom,msm-bus,num-cases = <2>;
		qcom,msm-bus,num-paths = <1>;
		qcom,msm-bus,vectors-KBps =
				<87 512 0 0>,
				<87 512 60000 960000>;
	};

	qcom,usbbam@f9304000 {
		status = "disabled";
		compatible = "qcom,usb-bam-msm";
		reg = <0xf9304000 0x5000>,
		      <0xf92f880c 0x4>;
		reg-names = "ssusb", "qscratch_ram1_reg";
		interrupts = <0 132 0>;
		interrupt-names = "ssusb";
		qcom,usb-bam-num-pipes = <16>;
		qcom,usb-bam-fifo-baseaddr = <0x00000000 0xf9200000>;
		qcom,ignore-core-reset-ack;
		qcom,disable-clk-gating;

		qcom,pipe0 {
			label = "ssusb-qdss-in-0";
			qcom,usb-bam-mem-type = <1>;
			qcom,bam-type = <0>;
			qcom,dir = <1>;
			qcom,pipe-num = <0>;
			qcom,peer-bam = <1>;
			qcom,src-bam-physical-address = <0xfc37C000>;
			qcom,src-bam-pipe-index = <0>;
			qcom,dst-bam-physical-address = <0xf9304000>;
			qcom,dst-bam-pipe-index = <2>;
			qcom,data-fifo-offset = <0xf0000>;
			qcom,data-fifo-size = <0x1800>;
			qcom,descriptor-fifo-offset = <0xf4000>;
			qcom,descriptor-fifo-size = <0x1400>;
			qcom,reset-bam-on-connect;
		};
	};

	spi_0: spi@f9923000 { /* BLSP1 QUP1 */
		compatible = "qcom,spi-qup-v2";
		#address-cells = <1>;
		#size-cells = <0>;
		reg-names = "spi_physical", "spi_bam_physical";
		reg = <0xf9923000 0x1000>,
		      <0xf9904000 0xf000>;
		interrupt-names = "spi_irq", "spi_bam_irq";
		interrupts = <0 95 0>, <0 238 0>;
		spi-max-frequency = <19200000>;
		qcom,gpio-mosi = <&msmgpio 0 0>;
		qcom,gpio-miso = <&msmgpio 1 0>;
		qcom,gpio-clk  = <&msmgpio 3 0>;
		qcom,gpio-cs0  = <&msmgpio 0 0>;

		qcom,infinite-mode = <0>;
		qcom,use-bam;
		qcom,ver-reg-exists;
		qcom,bam-consumer-pipe-index = <12>;
		qcom,bam-producer-pipe-index = <13>;
		qcom,master-id = <86>;
	};

	usb3: qcom,ssusb@f9200000 {
		compatible = "qcom,dwc-usb3-msm";
		reg = <0xf9200000 0xfc000>,
			 <0xfd4ab000 0x4>;
		#address-cells = <1>;
		#size-cells = <1>;
		ranges;

		interrupt-parent = <&usb3>;
		interrupts = <0 1>;
		#interrupt-cells = <1>;
		interrupt-map-mask = <0x0 0xffffffff>;
		interrupt-map = <0x0 0 &intc 0 133 0
				 0x0 1 &spmi_bus 0x0 0x0 0x9 0x0>;
		interrupt-names = "hs_phy_irq", "pmic_id_irq";

		USB3_GDSC-supply = <&gdsc_usb30>;
		qcom,dwc-usb3-msm-dbm-eps = <4>;
		qcom,otg-capability;
		qcom,misc-ref = <&pma8084_misc>;
		qcom,restore-sec-cfg-for-scm-dev-id = <9>;

		qcom,msm-bus,name = "usb3";
		qcom,msm-bus,num-cases = <2>;
		qcom,msm-bus,num-paths = <1>;
		qcom,msm-bus,vectors-KBps =
				<61 512 0 0>,
				<61 512 240000 960000>;

		dwc3@f9200000 {
			compatible = "synopsys,dwc3";
			reg = <0xf9200000 0xfc000>;
			interrupt-parent = <&intc>;
			interrupts = <0 131 0>, <0 179 0>;
			interrupt-names = "irq", "otg_irq";
			tx-fifo-resize;
			usb-phy = <&hsphy0>, <&ssphy0>;
		};
	};

	android_usb {
		compatible = "qcom,android-usb";
		qcom,android-usb-swfi-latency = <1>;
	};

	hsphy0: hsphy@f92f8800 {
		compatible = "qcom,usb-hsphy";
		reg = <0xf92f8800 0x3ff>,
			<0xfd4ab204 0x4>;
		qcom,hsphy-init = <0x00D191A4>;
		vdd-supply = <&pma8084_s1>;
		vdda18-supply = <&pma8084_l6>;
		vdda33-supply = <&pma8084_l24>;
		qcom,vdd-voltage-level = <0 900000 1050000>;
		qcom,ext-vbus-id;
		qcom,vbus-valid-override;
	};

	ssphy0: ssphy@f92f8800 {
		compatible = "qcom,usb-ssphy";
		reg = <0xf92f8800 0x3ff>;
		vdd-supply = <&pma8084_s1>;
		vdda18-supply = <&pma8084_l6>;
		qcom,vdd-voltage-level = <0 900000 1050000>;
		qcom,vbus-valid-override;
	};

	tsens: tsens@fc4a8000 {
		compatible = "qcom,msm-tsens";
		reg = <0xfc4a8000 0x2000>,
		      <0xfc4bc000 0x1000>;
		reg-names = "tsens_physical", "tsens_eeprom_physical";
		interrupts = <0 184 0>;
		qcom,sensors = <11>;
		qcom,slope = <3200 3200 3200 3200 3200 3200 3200 3200 3200
				3200 3200>;
		qcom,calib-mode = "fuse_map1";
	};

	xhci_hsic_host: qcom,xhci-msm-hsic@0xf9c00000 {
		compatible = "qcom,xhci-msm-hsic";
		reg = <0xf9c00000 0xfc000>;
		#address-cells = <0>;
		interrupt-parent = <&xhci_hsic_host>;
		interrupts = <0 1 2>;
		#interrupt-cells = <1>;
		interrupt-map-mask = <0xffffffff>;
		interrupt-map = <0 &intc 0 32 0
				1 &intc 0 29 0
				2 &msmgpio 107 0x4>;
		interrupt-names = "core_irq", "pwr_event_irq", "wakeup_irq";
		hsic-vdd-dig-supply = <&pma8084_s2_corner>;
		hsic-gdsc-supply = <&gdsc_usb_hsic>;
		hsic,strobe-gpio = <&msmgpio 134 0x00>;
		hsic,data-gpio = <&msmgpio 135 0x00>;
		qcom,vdd-voltage-level = <1 5 7>;

		qcom,msm-bus,name = "hsic";
		qcom,msm-bus,num-cases = <2>;
		qcom,msm-bus,num-paths = <1>;
		qcom,msm-bus,vectors-KBps =
				<85 512 0 0>,
			<85 512 40000 160000>;
	};

	qcom,ocmem@fdd00000 {
		compatible = "qcom,msm-ocmem";
		reg = <0xfdd00000 0x2000>,
		      <0xfdd02000 0x2000>,
		      <0xfe039000 0x400>,
		      <0xfec00000 0x200000>;
		reg-names = "ocmem_ctrl_physical", "dm_ctrl_physical", "br_ctrl_physical", "ocmem_physical";
		interrupts = <0 76 0 0 77 0>;
		interrupt-names = "ocmem_irq", "dm_irq";
		qcom,ocmem-num-regions = <0x4>;
		qcom,ocmem-num-macros = <0x20>;
		qcom,resource-type = <0x706d636f>;
		#address-cells = <1>;
		#size-cells = <1>;
		ranges = <0x0 0xfec00000 0x200000>;

		partition@0 {
			reg = <0x0 0x180000>;
			qcom,ocmem-part-name = "graphics";
			qcom,ocmem-part-min = <0x80000>;
		};

		partition@80000 {
			reg = <0x180000 0x80000>;
			qcom,ocmem-part-name = "lp_audio";
			qcom,ocmem-part-min = <0x80000>;
		};

		partition@100000 {
			reg = <0x180000 0x80000>;
			qcom,ocmem-part-name = "video";
			qcom,ocmem-part-min = <0x55000>;
		};

	};

	memory_hole: qcom,msm-mem-hole {
		compatible = "qcom,msm-mem-hole";
		qcom,memblock-remove = <0x0d400000 0x02a00000>; /* Address and Size of Hole */
	};

	qcom,ipc-spinlock@fd484000 {
		compatible = "qcom,ipc-spinlock-sfpb";
		reg = <0xfd484000 0x400>;
		qcom,num-locks = <8>;
	};

	qcom,smem@fa00000 {
		compatible = "qcom,smem";
		reg = <0xfa00000 0x200000>,
			<0xf9011000 0x1000>,
			<0xfc428000 0x4000>;
		reg-names = "smem", "irq-reg-base", "aux-mem1";

		qcom,smd-adsp {
			compatible = "qcom,smd";
			qcom,smd-edge = <1>;
			qcom,smd-irq-offset = <0x8>;
			qcom,smd-irq-bitmask = <0x100>;
			qcom,pil-string = "adsp";
			interrupts = <0 156 1>;
		};

		qcom,smsm-adsp {
			compatible = "qcom,smsm";
			qcom,smsm-edge = <1>;
			qcom,smsm-irq-offset = <0x8>;
			qcom,smsm-irq-bitmask = <0x200>;
			interrupts = <0 157 1>;
		};

		qcom,smd-rpm {
			compatible = "qcom,smd";
			qcom,smd-edge = <15>;
			qcom,smd-irq-offset = <0x8>;
			qcom,smd-irq-bitmask = <0x1>;
			interrupts = <0 168 1>;
			qcom,irq-no-suspend;
		};
	};

	qcom,venus@fdce0000 {
		compatible = "qcom,pil-venus";
		reg = <0xfdce0000 0x4000>,
		      <0xfdc80000 0x400>;
		reg-names = "wrapper_base", "vbif_base";
		vdd-supply = <&gdsc_venus>;

		qcom,firmware-name = "venus";
	};

	qcom,lpass@fe200000 {
		compatible = "qcom,pil-q6v5-lpass";
		reg = <0xfe200000 0x00100>,
		      <0xfd485100 0x00010>,
		      <0xfc4016c0 0x00004>;
		reg-names = "qdsp6_base", "halt_base", "restart_reg";
		vdd_cx-supply = <&pma8084_s2_corner>;
		interrupts = <0 162 1>;

		qcom,firmware-name = "adsp";

		/* GPIO inputs from lpass */
		qcom,gpio-err-fatal = <&smp2pgpio_ssr_smp2p_2_in 0 0>;
		qcom,gpio-proxy-unvote = <&smp2pgpio_ssr_smp2p_2_in 2 0>;
		qcom,gpio-err-ready = <&smp2pgpio_ssr_smp2p_2_in 1 0>;

		/* GPIO output to lpass */
		qcom,gpio-force-stop = <&smp2pgpio_ssr_smp2p_2_out 0 0>;
	};

	ufsphy1: ufsphy@0xfc597000 {
		compatible = "qcom,ufsphy";
		reg = <0xfc597000 0x87c>;
		vdda-phy-supply = <&pma8084_l4>;
		vdda-pll-supply = <&pma8084_l12>;
		vdda-phy-max-microamp = <50000>;
		vdda-pll-max-microamp = <1000>;

		status = "disabled";
	};

	ufs1: ufshc@0xfc594000 {
		compatible = "qcom,ufshc";
		reg = <0xfc594000 0x800>;
		interrupts = <0 28 0>;

		ufs-phy = <&ufsphy1>;
		vcc-supply = <&pma8084_l19>;
		vccq-supply = <&pma8084_l3>;
		vccq2-supply = <&pma8084_s4>;
		vcc-max-microamp = <460000>;
		vccq-max-microamp = <200000>;
		vccq2-max-microamp = <145000>;

		clock-names = "core_clk_src", "core_clk", "bus_clk", "iface_clk",
				"ref_clk", "rx_lane0_sync_clk", "tx_lane0_sync_clk",
				"rx_lane1_sync_clk", "tx_lane1_sync_clk";
		max-clock-frequency-hz = <200000000>, <0>, <0>, <0>,
						<0>, <0>, <0>, <0>, <0>;

		status = "disabled";
	};

	qcom,wdt@f9017000 {
		compatible = "qcom,msm-watchdog";
		reg = <0xf9017000 0x1000>;
		interrupts = <0 3 0>, <0 4 0>;
		qcom,bark-time = <11000>;
		qcom,pet-time = <10000>;
		qcom,ipi-ping;
	};

	qcom,tz-log@fe805720 {
		compatible = "qcom,tz-log";
		reg = <0xfe805720 0x1000>;
	};

	qcom,msm-rng@f9bff000{
		compatible = "qcom,msm-rng";
		reg = <0xf9bff000 0x200>;
		qcom,msm-rng-iface-clk;
	};

	jtag_fuse: jtagfuse@fc4be024 {
		compatible = "qcom,jtag-fuse";
		reg = <0xfc4be024 0x8>;
		reg-names = "fuse-base";
	};

	qcom,bcl {
		compatible = "qcom,bcl";
	};

	qcom,msm-thermal {
		compatible = "qcom,msm-thermal";
		qcom,sensor-id = <5>;
		qcom,poll-ms = <250>;
		qcom,limit-temp = <60>;
		qcom,temp-hysteresis = <10>;
		qcom,freq-step = <2>;
		qcom,freq-control-mask = <0xf>;
		qcom,core-limit-temp = <80>;
		qcom,core-temp-hysteresis = <10>;
		qcom,core-control-mask = <0xe>;
		qcom,hotplug-temp = <110>;
		qcom,hotplug-temp-hysteresis = <20>;
		qcom,cpu-sensors = "tsens_tz_sensor5", "tsens_tz_sensor6",
				"tsens_tz_sensor7", "tsens_tz_sensor8";
		qcom,vdd-restriction-temp = <5>;
		qcom,vdd-restriction-temp-hysteresis = <10>;
		qcom,pmic-sw-mode-temp = <85>;
		qcom,pmic-sw-mode-temp-hysteresis = <75>;
		qcom,pmic-sw-mode-regs = "vdd-dig";

		vdd-dig-supply = <&pma8084_s2_floor_corner>;
		vdd-gfx-supply = <&pma8084_s6_floor_corner>;

		qcom,vdd-dig-rstr{
			qcom,vdd-rstr-reg = "vdd-dig";
			qcom,levels = <5 7 7>; /* Nominal, Super Turbo, Super Turbo */
			qcom,min-level = <1>; /* No Request */
		};

		qcom,vdd-gfx-rstr{
			qcom,vdd-rstr-reg = "vdd-gfx";
			qcom,levels = <5 7 7>; /* Nominal, Super Turbo, Super Turbo */
			qcom,min-level = <1>; /* No Request */
		};

		qcom,vdd-apps-rstr{
			qcom,vdd-rstr-reg = "vdd-apps";
			qcom,levels = <1958400 2150400 2150400>;
			qcom,freq-req;
		};
	};

	msm_vidc: qcom,vidc@fdc00000 {
		compatible = "qcom,msm-vidc";
		reg = <0xfdc00000 0xff000>;
		interrupts = <0 44 0>;
		qcom,hfi = "venus";
		qcom,ocmem-size = <524288>; /* 512 * 1024*/
		qcom,max-hw-load = <1281600>; /* Full 4k @ 30 + 1080p @ 30 */
		qcom,vidc-ns-map = <0x40000000 0x40000000>;
		venus-supply = <&gdsc_venus>;
		venus-core0-supply = <&gdsc_venus_core0>;
		venus-core1-supply = <&gdsc_venus_core1>;
		qcom,clock-names= "core_clk", "core0_clk", "core1_clk", "iface_clk", "bus_clk", "mem_clk";
		qcom,clock-configs = <0x3 0x0 0x0 0x0 0x0 0x0>;
		qcom,load-freq-tbl = <979200 465000000>,
			<783360 465000000>,
			<489600 266670000>,
			<244800 133330000>;
		qcom,bus-ports = <1>;
		qcom,reg-presets = <0x800B0 0x00101001>,
			<0x800B0 0x00101001>,
			<0x800B4 0x00101010>,
			<0x800B8 0x10100010>,
			<0x800BC 0x00001010>,
			<0x800C0 0x1000100f>,
			<0x800C4 0x10000000>,
			<0x800C8 0x10001000>,
			<0x800CC 0x00001000>,
			<0x80070 0x00013FFF>,
			<0x80074 0x000000A4>,
			<0x800A8 0x00003FFF>,
			<0xe0020 0x5555556>,
			<0xe0024 0>,
			<0x80124 0x3>;
		qcom,enc-ocmem-ab-ib = <0 0>,
			<138000 1034000>,
			<414000 1034000>,
			<940000 1034000>,
			<1880000 2068000>,
			<3008000 3309000>,
			<3760000 4136000>,
			<4468000 2457000>;
		qcom,dec-ocmem-ab-ib = <0 0>,
			<176000 519000>,
			<456000 519000>,
			<864000 519000>,
			<1728000 1038000>,
			<2766000 1661000>,
			<3456000 2076000>,
			<3662000 2198000>;
		qcom,enc-ddr-ab-ib = <0 0>,
			<120000 302000>,
			<364000 302000>,
			<804000 302000>,
			<1608000 604000>,
			<2576000 967000>,
			<4680000 1404000>,
			<49880000 1496000>;
		qcom,dec-ddr-ab-ib = <0 0>,
			<208000 303000>,
			<536000 303000>,
			<1012000 303000>,
			<2024000 606000>,
			<3240000 970000>,
			<4048000 1212000>,
			<4264000 1279000>;
		qcom,buffer-type-tz-usage-table = <0x91 0x1>,
			<0x42 0x2>,
			<0x120 0x3>;
		qcom,vidc-iommu-domains {
			qcom,domain-ns {
				qcom,vidc-domain-phandle = <&venus_domain_ns>;
				qcom,vidc-partition-buffer-types = <0x1ff>,
					<0x200>;
			};
			qcom,domain-sec-bs {
				qcom,vidc-domain-phandle = <&venus_domain_sec_bitstream>;
				qcom,vidc-partition-buffer-types = <0x91>;
			};
			qcom,domain-sec-px {
				qcom,vidc-domain-phandle = <&venus_domain_sec_pixel>;
				qcom,vidc-partition-buffer-types = <0x42>;
			};
			qcom,domain-sec-np {
				qcom,vidc-domain-phandle = <&venus_domain_sec_non_pixel>;
				qcom,vidc-partition-buffer-types = <0x120>;
			};
		};
	};

	qcom,msm-adsp-sensors {
		compatible = "qcom,msm-adsp-sensors";
		qcom,src-id = <11>;
		qcom,dst-id = <604>;
		qcom,ab = <32505856>;
		qcom,ib = <32505856>;
	};

	sound {
		compatible = "qcom,apq8084-audio-taiko";
		qcom,model = "apq8084-taiko-snd-card";

		qcom,audio-routing =
			"RX_BIAS", "MCLK",
			"LDO_H", "MCLK",
			"AIF4 MAD", "MCLK",
			"AMIC1", "MIC BIAS1 Internal1",
			"MIC BIAS1 Internal1", "Handset Mic",
			"AMIC2", "MIC BIAS2 External",
			"MIC BIAS2 External", "Headset Mic",
			"AMIC3", "MIC BIAS2 External",
			"MIC BIAS2 External", "ANCRight Headset Mic",
			"AMIC4", "MIC BIAS2 External",
			"MIC BIAS2 External", "ANCLeft Headset Mic",
			"DMIC1", "MIC BIAS3 External",
			"MIC BIAS3 External", "Digital Mic1",
			"DMIC2", "MIC BIAS4 External",
			"MIC BIAS4 External", "Digital Mic2",
			"DMIC3", "MIC BIAS1 External",
			"MIC BIAS1 External", "Digital Mic3",
			"DMIC4", "MIC BIAS1 External",
			"MIC BIAS1 External", "Digital Mic4",
			"DMIC5", "MIC BIAS3 External",
			"MIC BIAS3 External", "Digital Mic5",
			"DMIC6", "MIC BIAS3 External",
			"MIC BIAS3 External", "Digital Mic6";

		qcom,taiko-mclk-clk-freq = <9600000>;
		qcom,prim-auxpcm-gpio-clk  = <&msmgpio 87 0>;
		qcom,prim-auxpcm-gpio-sync = <&msmgpio 88 0>;
		qcom,prim-auxpcm-gpio-din  = <&msmgpio 89 0>;
		qcom,prim-auxpcm-gpio-dout = <&msmgpio 90 0>;
		qcom,prim-auxpcm-gpio-set = "prim-gpio-tert";
		qcom,sec-auxpcm-gpio-clk  = <&msmgpio 82 0>;
		qcom,sec-auxpcm-gpio-sync = <&msmgpio 83 0>;
		qcom,sec-auxpcm-gpio-din  = <&msmgpio 84 0>;
		qcom,sec-auxpcm-gpio-dout = <&msmgpio 85 0>;
	};

	qcom,msm-adsp-loader {
		compatible = "qcom,adsp-loader";
		qcom,adsp-state = <0>;
	};

	qcom,msm-pcm {
		compatible = "qcom,msm-pcm-dsp";
		qcom,msm-pcm-dsp-id = <0>;
	};

	qcom,msm-pcm-low-latency {
		compatible = "qcom,msm-pcm-dsp";
		qcom,msm-pcm-dsp-id = <1>;
		qcom,msm-pcm-low-latency;
	};

	qcom,msm-pcm-routing {
		compatible = "qcom,msm-pcm-routing";
	};

	qcom,msm-pcm-lpa {
		compatible = "qcom,msm-pcm-lpa";
	};

	qcom,msm-compr-dsp {
		compatible = "qcom,msm-compr-dsp";
	};

	qcom,msm-voip-dsp {
		compatible = "qcom,msm-voip-dsp";
	};

	qcom,msm-pcm-voice {
		compatible = "qcom,msm-pcm-voice";
	};

	qcom,msm-stub-codec {
		compatible = "qcom,msm-stub-codec";
	};

	qcom,msm-dai-fe {
		compatible = "qcom,msm-dai-fe";
	};

	qcom,msm-pcm-afe {
		compatible = "qcom,msm-pcm-afe";
	};

	qcom,msm-dai-q6-hdmi {
		compatible = "qcom,msm-dai-q6-hdmi";
		qcom,msm-dai-q6-dev-id = <8>;
	};

	qcom,msm-lsm-client {
		compatible = "qcom,msm-lsm-client";
	};

	qcom,msm-dai-stub {
		compatible = "qcom,msm-dai-stub";
		qcom,msm-dai-stub-rx {
			compatible = "qcom,msm-dai-stub-dev";
			qcom,msm-dai-stub-dev-id = <0>;
		};

		qcom,msm-dai-stub-tx {
			compatible = "qcom,msm-dai-stub-dev";
			qcom,msm-dai-stub-dev-id = <1>;
		};

		qcom,msm-dai-stub-1-tx {
			compatible = "qcom,msm-dai-stub-dev";
			qcom,msm-dai-stub-dev-id = <3>;
		};
	};

	qcom,msm-dai-q6 {
		compatible = "qcom,msm-dai-q6";
		qcom,msm-dai-q6-sb-0-rx {
			compatible = "qcom,msm-dai-q6-dev";
			qcom,msm-dai-q6-dev-id = <16384>;
		};

		qcom,msm-dai-q6-sb-0-tx {
			compatible = "qcom,msm-dai-q6-dev";
			qcom,msm-dai-q6-dev-id = <16385>;
		};

		qcom,msm-dai-q6-sb-1-rx {
			compatible = "qcom,msm-dai-q6-dev";
			qcom,msm-dai-q6-dev-id = <16386>;
		};

		qcom,msm-dai-q6-sb-1-tx {
			compatible = "qcom,msm-dai-q6-dev";
			qcom,msm-dai-q6-dev-id = <16387>;
		};

		qcom,msm-dai-q6-sb-2-rx {
			compatible = "qcom,msm-dai-q6-dev";
			qcom,msm-dai-q6-dev-id = <16388>;
		};

		qcom,msm-dai-q6-sb-2-tx {
			compatible = "qcom,msm-dai-q6-dev";
			qcom,msm-dai-q6-dev-id = <16389>;
		};

		qcom,msm-dai-q6-sb-3-rx {
			compatible = "qcom,msm-dai-q6-dev";
			qcom,msm-dai-q6-dev-id = <16390>;
		};

		qcom,msm-dai-q6-sb-3-tx {
			compatible = "qcom,msm-dai-q6-dev";
			qcom,msm-dai-q6-dev-id = <16391>;
		};

		qcom,msm-dai-q6-sb-4-rx {
			compatible = "qcom,msm-dai-q6-dev";
			qcom,msm-dai-q6-dev-id = <16392>;
		};

		qcom,msm-dai-q6-sb-4-tx {
			compatible = "qcom,msm-dai-q6-dev";
			qcom,msm-dai-q6-dev-id = <16393>;
		};

		qcom,msm-dai-q6-sb-5-tx {
			compatible = "qcom,msm-dai-q6-dev";
			qcom,msm-dai-q6-dev-id = <16395>;
		};

		qcom,msm-dai-q6-bt-sco-rx {
			compatible = "qcom,msm-dai-q6-dev";
			qcom,msm-dai-q6-dev-id = <12288>;
		};

		qcom,msm-dai-q6-bt-sco-tx {
			compatible = "qcom,msm-dai-q6-dev";
			qcom,msm-dai-q6-dev-id = <12289>;
		};

		qcom,msm-dai-q6-int-fm-rx {
			compatible = "qcom,msm-dai-q6-dev";
			qcom,msm-dai-q6-dev-id = <12292>;
		};

		qcom,msm-dai-q6-int-fm-tx {
			compatible = "qcom,msm-dai-q6-dev";
			qcom,msm-dai-q6-dev-id = <12293>;
		};

		qcom,msm-dai-q6-be-afe-pcm-rx {
			compatible = "qcom,msm-dai-q6-dev";
			qcom,msm-dai-q6-dev-id = <224>;
		};

		qcom,msm-dai-q6-be-afe-pcm-tx {
			compatible = "qcom,msm-dai-q6-dev";
			qcom,msm-dai-q6-dev-id = <225>;
		};

		qcom,msm-dai-q6-afe-proxy-rx {
			compatible = "qcom,msm-dai-q6-dev";
			qcom,msm-dai-q6-dev-id = <241>;
		};

		qcom,msm-dai-q6-afe-proxy-tx {
			compatible = "qcom,msm-dai-q6-dev";
			qcom,msm-dai-q6-dev-id = <240>;
		};

		qcom,msm-dai-q6-incall-record-rx {
			compatible = "qcom,msm-dai-q6-dev";
			qcom,msm-dai-q6-dev-id = <32771>;
		};

		qcom,msm-dai-q6-incall-record-tx {
			compatible = "qcom,msm-dai-q6-dev";
			qcom,msm-dai-q6-dev-id = <32772>;
		};

		qcom,msm-dai-q6-incall-music-rx {
			compatible = "qcom,msm-dai-q6-dev";
			qcom,msm-dai-q6-dev-id = <32773>;
		};
	};

	qcom,msm-pri-auxpcm {
		compatible = "qcom,msm-auxpcm-dev";
		qcom,msm-cpudai-auxpcm-mode = <0>, <0>;
		qcom,msm-cpudai-auxpcm-sync = <1>, <1>;
		qcom,msm-cpudai-auxpcm-frame = <5>, <4>;
		qcom,msm-cpudai-auxpcm-quant = <2>, <2>;
		qcom,msm-cpudai-auxpcm-slot = <1>, <1>;
		qcom,msm-cpudai-auxpcm-data = <0>, <0>;
		qcom,msm-cpudai-auxpcm-pcm-clk-rate = <2048000>, <2048000>;
		qcom,msm-auxpcm-interface = "primary";
	};

	qcom,msm-sec-auxpcm {
		compatible = "qcom,msm-auxpcm-dev";
		qcom,msm-cpudai-auxpcm-mode = <0>, <0>;
		qcom,msm-cpudai-auxpcm-sync = <1>, <1>;
		qcom,msm-cpudai-auxpcm-frame = <5>, <4>;
		qcom,msm-cpudai-auxpcm-quant = <2>, <2>;
		qcom,msm-cpudai-auxpcm-slot = <1>, <1>;
		qcom,msm-cpudai-auxpcm-data = <0>, <0>;
		qcom,msm-cpudai-auxpcm-pcm-clk-rate = <2048000>, <2048000>;
		qcom,msm-auxpcm-interface = "secondary";
	};

	qcom,msm-dai-mi2s {
		compatible = "qcom,msm-dai-mi2s";
		qcom,msm-dai-q6-mi2s-quat {
			compatible = "qcom,msm-dai-q6-mi2s";
			qcom,msm-dai-q6-mi2s-dev-id = <3>;
			qcom,msm-mi2s-rx-lines = <1>;
			qcom,msm-mi2s-tx-lines = <2>;
		};
	};

	qcom,msm-pcm-hostless {
		compatible = "qcom,msm-pcm-hostless";
	};
};

&gdsc_venus {
	status = "ok";
};

&gdsc_venus_core0 {
	qcom,support-hw-trigger;
	status = "ok";
};

&gdsc_venus_core1 {
	qcom,support-hw-trigger;
	status = "ok";
};

&gdsc_vpu {
	qcom,clock-names = "core_clk", "maple_clk";
	status = "ok";
};

&gdsc_mdss {
	qcom,clock-names = "core_clk", "lut_clk";
	status = "ok";
};

&gdsc_jpeg {
	status = "ok";
};

&gdsc_vfe {
	qcom,clock-names = "core0_clk", "core1_clk", "cpp_clk";
	status = "ok";
};

&gdsc_oxili_gx {
	qcom,clock-names = "core_clk";
	status = "ok";
	parent-supply = <&pma8084_s6_corner>;
};

&gdsc_oxili_cx {
	status = "ok";
};

&gdsc_usb_hsic {
	status = "ok";
};

&gdsc_pcie_0{
	status = "ok";
};

&gdsc_pcie_1{
	status = "ok";
};

&gdsc_usb30{
	status = "ok";
};

&gdsc_usb30_sec{
	status = "ok";
};

/include/ "msm-pma8084-rpm-regulator.dtsi"
/include/ "msm-pma8084.dtsi"
/include/ "apq8084-regulator.dtsi"

&pma8084_vadc {
	chan@73 {
		label = "apq_therm";
		reg = <0x73>;
		qcom,decimation = <0>;
		qcom,pre-div-channel-scaling = <0>;
		qcom,calibration-type = "ratiometric";
		qcom,scale-function = <2>;
		qcom,hw-settle-time = <2>;
		qcom,fast-avg-setup = <0>;
	};

	chan@77 {
		label = "quiet_therm";
		reg = <0x77>;
		qcom,decimation = <0>;
		qcom,pre-div-channel-scaling = <0>;
		qcom,calibration-type = "ratiometric";
		qcom,scale-function = <2>;
		qcom,hw-settle-time = <2>;
		qcom,fast-avg-setup = <0>;
	};
};

&pma8084_adc_tm {
	chan@8 {
		label = "die_temp";
		reg = <8>;
		qcom,decimation = <0>;
		qcom,pre-div-channel-scaling = <0>;
		qcom,calibration-type = "absolute";
		qcom,scale-function = <3>;
		qcom,hw-settle-time = <0>;
		qcom,fast-avg-setup = <3>;
		qcom,btm-channel-number = <0x48>;
	};

	chan@73 {
		label = "apq_therm";
		reg = <0x73>;
		qcom,decimation = <0>;
		qcom,pre-div-channel-scaling = <0>;
		qcom,calibration-type = "ratiometric";
		qcom,scale-function = <2>;
		qcom,hw-settle-time = <2>;
		qcom,fast-avg-setup = <3>;
		qcom,btm-channel-number = <0x68>;
		qcom,thermal-node;
	};

	chan@77 {
		label = "quiet_therm";
		reg = <0x77>;
		qcom,decimation = <0>;
		qcom,pre-div-channel-scaling = <0>;
		qcom,calibration-type = "ratiometric";
		qcom,scale-function = <2>;
		qcom,hw-settle-time = <2>;
		qcom,fast-avg-setup = <3>;
		qcom,btm-channel-number = <0x70>;
		qcom,thermal-node;
	};
};

&krait_regulator_pmic {
	status = "ok";

	qcom,ctl@2900 {
		status = "ok";
	};

	qcom,ps@2a00 {
		status = "ok";
	};

	qcom,freq@2b00 {
		status = "ok";
	};
};
